AUTOSAR XML (schema 00044)
package /AppDataAResourceConsumption/SwAddrMethods
  sw addr method CODE: memory-allocation-keyword-policy=ADDR-METHOD-SHORT-NAME, section-type=CODE
package /ComponentTypes
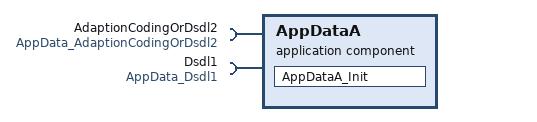
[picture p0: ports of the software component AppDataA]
  application sw component type AppDataA
    require port AdaptionCodingOrDsdl2: client-com-spec=AppData_AdaptionCodingOrDsdl2/Data, required-interface=AppData_AdaptionCodingOrDsdl2
    require port Dsdl1: required-com-specs=[AdrRange, AppData_Dsdl1/Data], required-interface=AppData_Dsdl1
    behavior AppDataA_InternalBehavior
      init event AppDataA_InitEvent: start-on-event=AppDataA_Init
      runnable AppDataA_Init
        sync call SC_AdaptionCodingOrDsdl2_Data: operation=AdaptionCodingOrDsdl2.Data, timeout=0
        sync call SC_Dsdl1_AdrRange: operation=Dsdl1.AdrRange, timeout=0
        sync call SC_Dsdl1_Data: operation=Dsdl1.Data, timeout=0
  swc implementation AppDataA_Implementation: vendor-id=75, behavior=AppDataA_InternalBehavior
    code-descriptors:
      code Default: artifact-descriptors=autosar-engineering-object={short-label=Default, category=SWSRC}
    resource consumption ResourceConsumption
      memory section CODE: sw-addrmethod=CODE
package /DataTypes
  impl type AppData_Data128Byte: category=ARRAY, sw-calibration-access=READ-ONLY, type-emitter=RTE
    element Element: array-size=128, array-size-semantics=FIXED-SIZE, implementation-data-type=uint8
  impl type AppData_Dsdl1InfoList_Type: category=ARRAY, sw-calibration-access=READ-ONLY, type-emitter=RTE
    element Element: array-size=120, array-size-semantics=FIXED-SIZE, implementation-data-type=uint8
package /PortInterfaces
  client server interface AppData_AdaptionCodingOrDsdl2
    operation Data: possible-error=[AppData_AdaptionCodingOrDsdl2/E_NOT_OK, E_PENDING, AppData_AdaptionCodingOrDsdl2/E_WAIT_FOR_DATA]
      4 x arg, all with server-argument-impl-policy=USE-ARGUMENT-TYPE:
        cmd: type=uint8, direction=IN
        id: type=uint16, direction=IN
        ptrResultData: type=AppData_Data128Byte, direction=OUT
        ptrResultDataLength: type=uint16, direction=OUT
    error E_NOT_OK: error-code=1
    error E_PENDING: error-code=10
    error E_WAIT_FOR_DATA: error-code=2
  client server interface AppData_Dsdl1
    operation AdrRange: possible-error=[AppData_Dsdl1/E_NOT_OK, AppData_Dsdl1/E_WAIT_FOR_DATA]
      arg dsAdrStart: type=uint16, direction=OUT, server-argument-impl-policy=USE-ARGUMENT-TYPE
      arg dsAdrEnd: type=uint16, direction=OUT, server-argument-impl-policy=USE-ARGUMENT-TYPE
    operation Data: possible-error=[AppData_Dsdl1/E_NOT_OK, AppData_Dsdl1/E_WAIT_FOR_DATA]
      arg datasetInfoList: type=AppData_Dsdl1InfoList_Type, direction=INOUT, server-argument-impl-policy=USE-ARGUMENT-TYPE
    error E_NOT_OK: error-code=1
    error E_WAIT_FOR_DATA: error-code=2
